AUTOSAR XML (schema 4-2-2)
package /ASW_StbM
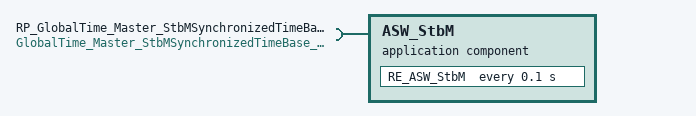
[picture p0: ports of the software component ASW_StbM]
  application sw component type ASW_StbM
    require port RP_GlobalTime_Master_StbMSynchronizedTimeBase_Eth: required-interface=GlobalTime_Master_StbMSynchronizedTimeBase_Eth
    behavior SwcInternalBehavior
      timing event TimingEvent_0: start-on-event=RE_ASW_StbM, period=0.1
      runnable RE_ASW_StbM: symbol=RE_ASW_StbM_func
        5 x sync call:
          SynchronousServerCallPoint_4: operation=RP_GlobalTime_Master_StbMSynchronizedTimeBase_Eth.SetGlobalTime
          SynchronousServerCallPoint_5: operation=RP_GlobalTime_Master_StbMSynchronizedTimeBase_Eth.UpdateGlobalTime
          SynchronousServerCallPoint_6: operation=RP_GlobalTime_Master_StbMSynchronizedTimeBase_Eth.GetMasterConfig
          SynchronousServerCallPoint_7: operation=RP_GlobalTime_Master_StbMSynchronizedTimeBase_Eth.SetUserData
          SynchronousServerCallPoint_8: operation=RP_GlobalTime_Master_StbMSynchronizedTimeBase_Eth.TriggerTimeTransmission
